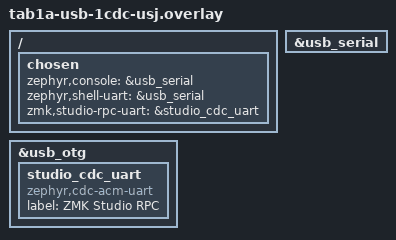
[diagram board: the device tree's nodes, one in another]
/*
 * Copyright (c) 2026 The ZMK Contributors
 *
 * SPDX-License-Identifier: MIT
 *
 * Tab1a USB build: HID + one Studio-RPC CDC; console/shell on USB-Serial/JTAG —
 * enumeration only: the console goes dark by design once the OTG PHY hand-off runs.
 *   sh zmk/esp-port/build_cobantab1a.sh -O zmk/esp-port/bringup/tab1a-usb-1cdc-usj.overlay
 * Applied AFTER the shield overlay, so every chosen here wins.
 * Unfused board: GPIO19/20 boot into USB-Serial/JTAG (flash.sh works); the
 * DWC2 driver hands them to OTG when the device stack starts, any reset reverts.
 */

/ {
    chosen {
        /* Console = Serial/JTAG: it works from reset (the ROM uses it too),
         * but dies at the PHY hand-off below — boot logs there are a
         * diagnostic, not a contract. */
        zephyr,console = &usb_serial;
        zephyr,shell-uart = &usb_serial;

        zmk,studio-rpc-uart = &studio_cdc_uart;
    };
};

/* The zephyr_udc0 label is mandatory (app/src/usb.c #error); binding it
 * enables the SoC's DWC2 device controller. */
zephyr_udc0: &usb_otg {
    status = "okay";

    /* No more than two CDCs fit on this composite: 6 IN EPs =
     * EP0 + HID + 2x(CDC data + CDC notify). */
    studio_cdc_uart: studio_cdc_uart {
        compatible = "zephyr,cdc-acm-uart";
        label = "ZMK Studio RPC";
    };

};

&usb_serial {
    status = "disabled";
};

/* Diagnostic-only: keep Serial/JTAG alive as the console (goes dark if the
 * OTG PHY hand-off ever runs). */
&usb_serial {
    status = "okay";
};
